# LPC55S66_cm33_core1 register map
Vendor: nxp.com; File version: 1.0
CPU: CM33 r2p0, little endian, no MPU, no FPU, VTOR, 3 interrupt priority bits
Registers are 32-bit, read-write, reset 0x0 unless marked. A register's access mark holds for its fields unless they carry their own. Offsets are from the block's base; [hi:lo] are bit positions; {n}, {i} and the like mark numbered series.

## FLASH
Base 0x40034000
0x00 CMD wo — command register
  [31:0] CMD — command register.
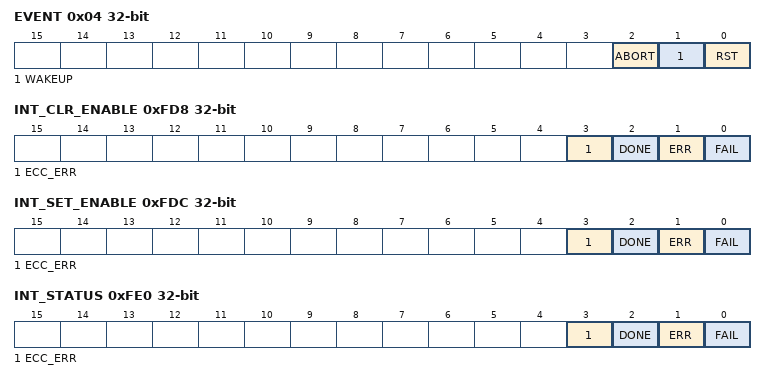
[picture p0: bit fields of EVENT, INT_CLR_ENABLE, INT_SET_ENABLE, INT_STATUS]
0x04 EVENT wo
  [2] ABORT — When bit is set, a running program/erase command is aborted.
  [1] WAKEUP — When bit is set, the controller wakes up from whatever low power or powerdown mode was active.
  [0] RST — When bit is set, the controller and flash are reset.
0x10 STARTA — start (or only) address for next flash command
  [17:0] STARTA — Address / Start address for commands that take an address (range) as a parameter.
0x14 STOPA — end address for next flash command, if command operates on address ranges
  [17:0] STOPA — Stop address for commands that take an address range as a parameter (the word specified by STOPA is included in the address range).
{0x80+4i} DATAW[{i}] (i=0..3) — data register, word 0-7; Memory data, or command parameter, or command result.
  [31:0] DATAW
0xFD8 INT_CLR_ENABLE wo — Clear interrupt enable bits
  [3] ECC_ERR — When a CLR_ENABLE bit is written to 1, the corresponding INT_ENABLE bit is cleared.
  [2] DONE — When a CLR_ENABLE bit is written to 1, the corresponding INT_ENABLE bit is cleared.
  [1] ERR — When a CLR_ENABLE bit is written to 1, the corresponding INT_ENABLE bit is cleared.
  [0] FAIL — When a CLR_ENABLE bit is written to 1, the corresponding INT_ENABLE bit is cleared.
0xFDC INT_SET_ENABLE wo — Set interrupt enable bits
  [3] ECC_ERR — When a SET_ENABLE bit is written to 1, the corresponding INT_ENABLE bit is set.
  [2] DONE — When a SET_ENABLE bit is written to 1, the corresponding INT_ENABLE bit is set.
  [1] ERR — When a SET_ENABLE bit is written to 1, the corresponding INT_ENABLE bit is set.
  [0] FAIL — When a SET_ENABLE bit is written to 1, the corresponding INT_ENABLE bit is set.
0xFE0 INT_STATUS — Interrupt status bits
  [3] ECC_ERR ro — This status bit is set if, during a memory read operation (either a user-requested read, or a speculative read, or reads performed by a controller command), a correctable or uncorrectable error is detected by ECC decoding logic.
  [2] DONE ro — This status bit is set at the end of command execution.
  [1] ERR ro — This status bit is set if execution of an illegal command is detected.
  [0] FAIL ro — This status bit is set if execution of a (legal) command failed.
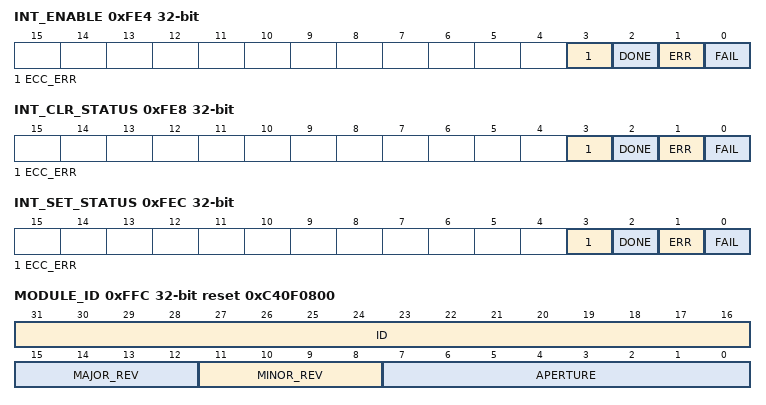
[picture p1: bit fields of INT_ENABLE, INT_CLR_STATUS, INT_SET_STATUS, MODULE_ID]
0xFE4 INT_ENABLE — Interrupt enable bits
  [3] ECC_ERR ro — If an INT_ENABLE bit is set, an interrupt request will be generated if the corresponding INT_STATUS bit is high.
  [2] DONE ro — If an INT_ENABLE bit is set, an interrupt request will be generated if the corresponding INT_STATUS bit is high.
  [1] ERR ro — If an INT_ENABLE bit is set, an interrupt request will be generated if the corresponding INT_STATUS bit is high.
  [0] FAIL ro — If an INT_ENABLE bit is set, an interrupt request will be generated if the corresponding INT_STATUS bit is high.
0xFE8 INT_CLR_STATUS wo — Clear interrupt status bits
  [3] ECC_ERR — When a CLR_STATUS bit is written to 1, the corresponding INT_STATUS bit is cleared.
  [2] DONE — When a CLR_STATUS bit is written to 1, the corresponding INT_STATUS bit is cleared.
  [1] ERR — When a CLR_STATUS bit is written to 1, the corresponding INT_STATUS bit is cleared.
  [0] FAIL — When a CLR_STATUS bit is written to 1, the corresponding INT_STATUS bit is cleared.
0xFEC INT_SET_STATUS wo — Set interrupt status bits
  [3] ECC_ERR — When a SET_STATUS bit is written to 1, the corresponding INT_STATUS bit is set.
  [2] DONE — When a SET_STATUS bit is written to 1, the corresponding INT_STATUS bit is set.
  [1] ERR — When a SET_STATUS bit is written to 1, the corresponding INT_STATUS bit is set.
  [0] FAIL — When a SET_STATUS bit is written to 1, the corresponding INT_STATUS bit is set.
0xFFC MODULE_ID ro reset 0xC40F0800 — Controller+Memory module identification
  [31:16] ID — Identifier.
  [15:12] MAJOR_REV — Major revision i.
  [11:8] MINOR_REV — Minor revision i.
  [7:0] APERTURE — Aperture i.
